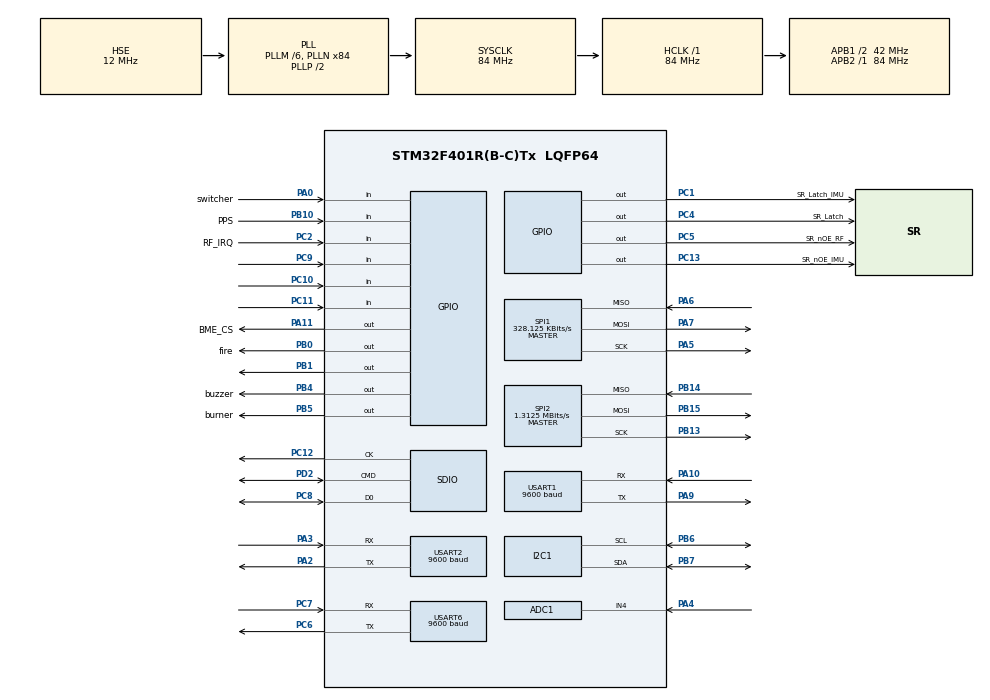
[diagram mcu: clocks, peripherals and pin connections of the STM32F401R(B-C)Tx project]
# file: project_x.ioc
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ADC1.Channel-0\#ChannelRegularConversion=ADC_CHANNEL_4
ADC1.NbrOfConversionFlag=1
ADC1.Rank-0\#ChannelRegularConversion=1
ADC1.SamplingTime-0\#ChannelRegularConversion=ADC_SAMPLETIME_3CYCLES
ADC1.master=1
Dma.Request0=SDIO_TX
Dma.Request1=SDIO_RX
Dma.SDIO_RX.1.Direction=DMA_PERIPH_TO_MEMORY
Dma.SDIO_RX.1.FIFOMode=DMA_FIFOMODE_ENABLE
Dma.SDIO_RX.1.FIFOThreshold=DMA_FIFO_THRESHOLD_FULL
Dma.SDIO_RX.1.Instance=DMA2_Stream6
Dma.SDIO_RX.1.MemBurst=DMA_MBURST_INC4
Dma.SDIO_RX.1.MemDataAlignment=DMA_MDATAALIGN_WORD
Dma.SDIO_RX.1.MemInc=DMA_MINC_ENABLE
Dma.SDIO_RX.1.Mode=DMA_PFCTRL
Dma.SDIO_RX.1.PeriphBurst=DMA_PBURST_INC4
Dma.SDIO_RX.1.PeriphDataAlignment=DMA_PDATAALIGN_WORD
Dma.SDIO_RX.1.PeriphInc=DMA_PINC_DISABLE
Dma.SDIO_RX.1.Priority=DMA_PRIORITY_LOW
Dma.SDIO_TX.0.Direction=DMA_MEMORY_TO_PERIPH
Dma.SDIO_TX.0.FIFOMode=DMA_FIFOMODE_ENABLE
Dma.SDIO_TX.0.FIFOThreshold=DMA_FIFO_THRESHOLD_FULL
Dma.SDIO_TX.0.Instance=DMA2_Stream3
Dma.SDIO_TX.0.MemBurst=DMA_MBURST_INC4
Dma.SDIO_TX.0.MemDataAlignment=DMA_MDATAALIGN_WORD
Dma.SDIO_TX.0.MemInc=DMA_MINC_ENABLE
Dma.SDIO_TX.0.Mode=DMA_PFCTRL
Dma.SDIO_TX.0.PeriphBurst=DMA_PBURST_INC4
Dma.SDIO_TX.0.PeriphDataAlignment=DMA_PDATAALIGN_WORD
Dma.SDIO_TX.0.PeriphInc=DMA_PINC_DISABLE
Dma.SDIO_TX.0.Priority=DMA_PRIORITY_LOW
FATFS._FS_LOCK=10
FATFS._MAX_SS=4096
FATFS._USE_LFN=1
Mcu.Family=STM32F4
Mcu.Name=STM32F401R(B-C)Tx
Mcu.Package=LQFP64
NVIC.DMA2_Stream3_IRQn=true\:0\:0\:false\:false\:true\:false\:true
NVIC.DMA2_Stream6_IRQn=true\:0\:0\:false\:false\:true\:false\:true
NVIC.PriorityGroup=NVIC_PRIORITYGROUP_4
NVIC.USART1_IRQn=true\:0\:0\:false\:false\:true\:true\:true
NVIC.USART6_IRQn=true\:0\:0\:false\:false\:true\:true\:true
PA0-WKUP.GPIO_Label=switcher
PA0-WKUP.Signal=GPIO_Input
PA10.Mode=Asynchronous
PA10.Signal=USART1_RX
PA11.GPIO_Label=BME_CS
PA11.Signal=GPIO_Output
PA13.Mode=Serial_Wire
PA13.Signal=SYS_JTMS-SWDIO
PA14.Mode=Serial_Wire
PA14.Signal=SYS_JTCK-SWCLK
PA2.Mode=Asynchronous
PA2.Signal=USART2_TX
PA3.Mode=Asynchronous
PA3.Signal=USART2_RX
PA4.Signal=ADCx_IN4
PA5.Mode=Full_Duplex_Master
PA5.Signal=SPI1_SCK
PA6.Mode=Full_Duplex_Master
PA6.Signal=SPI1_MISO
PA7.Mode=Full_Duplex_Master
PA7.Signal=SPI1_MOSI
PA9.Mode=Asynchronous
PA9.Signal=USART1_TX
PB0.GPIO_Label=fire
PB0.GPIO_ModeDefaultOutputPP=GPIO_MODE_OUTPUT_OD
PB0.GPIO_PuPd=GPIO_NOPULL
PB0.PinState=GPIO_PIN_SET
PB0.Signal=GPIO_Output
PB1.Signal=GPIO_Output
PB10.GPIO_Label=PPS
PB10.Signal=GPIO_Input
PB13.Mode=Full_Duplex_Master
PB13.Signal=SPI2_SCK
PB14.Mode=Full_Duplex_Master
PB14.Signal=SPI2_MISO
PB15.Mode=Full_Duplex_Master
PB15.Signal=SPI2_MOSI
PB4.GPIO_Label=buzzer
PB4.Signal=GPIO_Output
PB5.GPIO_Label=burner
PB5.Signal=GPIO_Output
PB6.Mode=I2C
PB6.Signal=I2C1_SCL
PB7.Mode=I2C
PB7.Signal=I2C1_SDA
PC1.GPIO_Label=SR_Latch_IMU
PC1.Signal=GPIO_Output
PC10.Signal=GPIO_Input
PC11.Signal=GPIO_Input
PC12.Mode=SD_1_bit
PC12.Signal=SDIO_CK
PC13-ANTI_TAMP.GPIO_Label=SR_nOE_IMU
PC13-ANTI_TAMP.Signal=GPIO_Output
PC2.GPIO_Label=RF_IRQ
PC2.Signal=GPIO_Input
PC4.GPIO_Label=SR_Latch
PC4.Signal=GPIO_Output
PC5.GPIO_Label=SR_nOE_RF
PC5.Signal=GPIO_Output
PC6.Mode=Asynchronous
PC6.Signal=USART6_TX
PC7.Mode=Asynchronous
PC7.Signal=USART6_RX
PC8.Mode=SD_1_bit
PC8.Signal=SDIO_D0
PC9.Signal=GPIO_Input
PD2.Mode=SD_1_bit
PD2.Signal=SDIO_CMD
PH0\ -\ OSC_IN.Mode=HSE-External-Oscillator
PH0\ -\ OSC_IN.Signal=RCC_OSC_IN
PH1\ -\ OSC_OUT.Mode=HSE-External-Oscillator
PH1\ -\ OSC_OUT.Signal=RCC_OSC_OUT
ProjectManager.HeapSize=0x200
ProjectManager.StackSize=0x400
ProjectManager.TargetToolchain=STM32CubeIDE
RCC.48MHZClocksFreq_Value=42000000
RCC.AHBFreq_Value=84000000
RCC.APB1CLKDivider=RCC_HCLK_DIV2
RCC.APB1Freq_Value=42000000
RCC.APB1TimFreq_Value=84000000
RCC.APB2Freq_Value=84000000
RCC.APB2TimFreq_Value=84000000
RCC.CortexFreq_Value=84000000
RCC.HCLKFreq_Value=84000000
RCC.HSE_VALUE=12000000
RCC.HSI_VALUE=16000000
RCC.LSE_VALUE=32768
RCC.PLLM=6
RCC.PLLN=84
RCC.PLLSourceVirtual=RCC_PLLSOURCE_HSE
RCC.SYSCLKFreq_VALUE=84000000
RCC.SYSCLKSource=RCC_SYSCLKSOURCE_PLLCLK
RCC.VCOOutputFreq_Value=168000000
SDIO.ClockDiv=20
SH.ADCx_IN4.0=ADC1_IN4,IN4
SPI1.BaudRatePrescaler=SPI_BAUDRATEPRESCALER_256
SPI1.CLKPhase=SPI_PHASE_2EDGE
SPI1.CLKPolarity=SPI_POLARITY_HIGH
SPI1.CalculateBaudRate=328.125 KBits/s
SPI1.Direction=SPI_DIRECTION_2LINES
SPI1.Mode=SPI_MODE_MASTER
SPI1.VirtualType=VM_MASTER
SPI2.BaudRatePrescaler=SPI_BAUDRATEPRESCALER_32
SPI2.CalculateBaudRate=1.3125 MBits/s
SPI2.Direction=SPI_DIRECTION_2LINES
SPI2.Mode=SPI_MODE_MASTER
SPI2.VirtualType=VM_MASTER
USART1.BaudRate=9600
USART1.VirtualMode=VM_ASYNC
USART2.BaudRate=9600
USART2.VirtualMode=VM_ASYNC
USART6.BaudRate=9600
USART6.VirtualMode=VM_ASYNC
VP_FATFS_VS_SDIO.Mode=SDIO
board=custom

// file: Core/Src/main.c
/* USER CODE BEGIN Header */
/**
  ******************************************************************************
  * @file           : main.c
  * @brief          : Main program body
  ******************************************************************************
  * @attention
  *
  * Copyright (c) 2023 STMicroelectronics.
  * All rights reserved.
  *
  * This software is licensed under terms that can be found in the LICENSE file
  * in the root directory of this software component.
  * If no LICENSE file comes with this software, it is provided AS-IS.
  *
  ******************************************************************************
  */
/* USER CODE END Header */
#include "main.h"
#include "fatfs.h"

ADC_HandleTypeDef hadc1;

I2C_HandleTypeDef hi2c1;

SD_HandleTypeDef hsd;
DMA_HandleTypeDef hdma_sdio_tx;
DMA_HandleTypeDef hdma_sdio_rx;

SPI_HandleTypeDef hspi1;
SPI_HandleTypeDef hspi2;

UART_HandleTypeDef huart1;
UART_HandleTypeDef huart2;
UART_HandleTypeDef huart6;

void SystemClock_Config(void);
static void MX_GPIO_Init(void);
static void MX_SPI2_Init(void);
static void MX_I2C1_Init(void);
static void MX_SDIO_SD_Init(void);
static void MX_ADC1_Init(void);
static void MX_USART1_UART_Init(void);
static void MX_USART2_UART_Init(void);
static void MX_USART6_UART_Init(void);
static void MX_DMA_Init(void);
static void MX_SPI1_Init(void);

/* USER CODE BEGIN 0 */
void app_main();
/* USER CODE END 0 */

int main(void)
{

  /* MCU Configuration--------------------------------------------------------*/

  /* Reset of all peripherals, Initializes the Flash interface and the Systick. */
  HAL_Init();

  /* Configure the system clock */
  SystemClock_Config();

  /* Initialize all configured peripherals */
  MX_GPIO_Init();
  MX_SPI2_Init();
  MX_I2C1_Init();
  MX_SDIO_SD_Init();
  MX_ADC1_Init();
  MX_USART1_UART_Init();
  MX_FATFS_Init();
  MX_USART2_UART_Init();
  MX_USART6_UART_Init();
  MX_DMA_Init();
  MX_SPI1_Init();
  /* USER CODE BEGIN 2 */
  app_main();
  /* USER CODE END 2 */

  /* Infinite loop */
  while (1)
  {

  }
}

void SystemClock_Config(void)
{
  RCC_OscInitTypeDef RCC_OscInitStruct = {0};
  RCC_ClkInitTypeDef RCC_ClkInitStruct = {0};

  /** Configure the main internal regulator output voltage
  */
  __HAL_RCC_PWR_CLK_ENABLE();
  __HAL_PWR_VOLTAGESCALING_CONFIG(PWR_REGULATOR_VOLTAGE_SCALE2);
  /** Initializes the RCC Oscillators according to the specified parameters
  * in the RCC_OscInitTypeDef structure.
  */
  RCC_OscInitStruct.OscillatorType = RCC_OSCILLATORTYPE_HSE;
  RCC_OscInitStruct.HSEState = RCC_HSE_ON;
  RCC_OscInitStruct.PLL.PLLState = RCC_PLL_ON;
  RCC_OscInitStruct.PLL.PLLSource = RCC_PLLSOURCE_HSE;
  RCC_OscInitStruct.PLL.PLLM = 6;
  RCC_OscInitStruct.PLL.PLLN = 84;
  RCC_OscInitStruct.PLL.PLLP = RCC_PLLP_DIV2;
  RCC_OscInitStruct.PLL.PLLQ = 4;
  if (HAL_RCC_OscConfig(&RCC_OscInitStruct) != HAL_OK)
  {
    Error_Handler();
  }
  /** Initializes the CPU, AHB and APB buses clocks
  */
  RCC_ClkInitStruct.ClockType = RCC_CLOCKTYPE_HCLK|RCC_CLOCKTYPE_SYSCLK
                              |RCC_CLOCKTYPE_PCLK1|RCC_CLOCKTYPE_PCLK2;
  RCC_ClkInitStruct.SYSCLKSource = RCC_SYSCLKSOURCE_PLLCLK;
  RCC_ClkInitStruct.AHBCLKDivider = RCC_SYSCLK_DIV1;
  RCC_ClkInitStruct.APB1CLKDivider = RCC_HCLK_DIV2;
  RCC_ClkInitStruct.APB2CLKDivider = RCC_HCLK_DIV1;

  if (HAL_RCC_ClockConfig(&RCC_ClkInitStruct, FLASH_LATENCY_2) != HAL_OK)
  {
    Error_Handler();
  }
}

static void MX_ADC1_Init(void)
{

  ADC_ChannelConfTypeDef sConfig = {0};

  /** Configure the global features of the ADC (Clock, Resolution, Data Alignment and number of conversion)
  */
  hadc1.Instance = ADC1;
  hadc1.Init.ClockPrescaler = ADC_CLOCK_SYNC_PCLK_DIV4;
  hadc1.Init.Resolution = ADC_RESOLUTION_12B;
  hadc1.Init.ScanConvMode = DISABLE;
  hadc1.Init.ContinuousConvMode = DISABLE;
  hadc1.Init.DiscontinuousConvMode = DISABLE;
  hadc1.Init.ExternalTrigConvEdge = ADC_EXTERNALTRIGCONVEDGE_NONE;
  hadc1.Init.ExternalTrigConv = ADC_SOFTWARE_START;
  hadc1.Init.DataAlign = ADC_DATAALIGN_RIGHT;
  hadc1.Init.NbrOfConversion = 1;
  hadc1.Init.DMAContinuousRequests = DISABLE;
  hadc1.Init.EOCSelection = ADC_EOC_SINGLE_CONV;
  if (HAL_ADC_Init(&hadc1) != HAL_OK)
  {
    Error_Handler();
  }
  /** Configure for the selected ADC regular channel its corresponding rank in the sequencer and its sample time.
  */
  sConfig.Channel = ADC_CHANNEL_4;
  sConfig.Rank = 1;
  sConfig.SamplingTime = ADC_SAMPLETIME_3CYCLES;
  if (HAL_ADC_ConfigChannel(&hadc1, &sConfig) != HAL_OK)
  {
    Error_Handler();
  }

}

static void MX_I2C1_Init(void)
{

  hi2c1.Instance = I2C1;
  hi2c1.Init.ClockSpeed = 100000;
  hi2c1.Init.DutyCycle = I2C_DUTYCYCLE_2;
  hi2c1.Init.OwnAddress1 = 0;
  hi2c1.Init.AddressingMode = I2C_ADDRESSINGMODE_7BIT;
  hi2c1.Init.DualAddressMode = I2C_DUALADDRESS_DISABLE;
  hi2c1.Init.OwnAddress2 = 0;
  hi2c1.Init.GeneralCallMode = I2C_GENERALCALL_DISABLE;
  hi2c1.Init.NoStretchMode = I2C_NOSTRETCH_DISABLE;
  if (HAL_I2C_Init(&hi2c1) != HAL_OK)
  {
    Error_Handler();
  }

}

static void MX_SDIO_SD_Init(void)
{

  hsd.Instance = SDIO;
  hsd.Init.ClockEdge = SDIO_CLOCK_EDGE_RISING;
  hsd.Init.ClockBypass = SDIO_CLOCK_BYPASS_DISABLE;
  hsd.Init.ClockPowerSave = SDIO_CLOCK_POWER_SAVE_DISABLE;
  hsd.Init.BusWide = SDIO_BUS_WIDE_1B;
  hsd.Init.HardwareFlowControl = SDIO_HARDWARE_FLOW_CONTROL_DISABLE;
  hsd.Init.ClockDiv = 20;

}

static void MX_SPI1_Init(void)
{

  /* SPI1 parameter configuration*/
  hspi1.Instance = SPI1;
  hspi1.Init.Mode = SPI_MODE_MASTER;
  hspi1.Init.Direction = SPI_DIRECTION_2LINES;
  hspi1.Init.DataSize = SPI_DATASIZE_8BIT;
  hspi1.Init.CLKPolarity = SPI_POLARITY_HIGH;
  hspi1.Init.CLKPhase = SPI_PHASE_2EDGE;
  hspi1.Init.NSS = SPI_NSS_SOFT;
  hspi1.Init.BaudRatePrescaler = SPI_BAUDRATEPRESCALER_256;
  hspi1.Init.FirstBit = SPI_FIRSTBIT_MSB;
  hspi1.Init.TIMode = SPI_TIMODE_DISABLE;
  hspi1.Init.CRCCalculation = SPI_CRCCALCULATION_DISABLE;
  hspi1.Init.CRCPolynomial = 10;
  if (HAL_SPI_Init(&hspi1) != HAL_OK)
  {
    Error_Handler();
  }

}

static void MX_SPI2_Init(void)
{

  /* SPI2 parameter configuration*/
  hspi2.Instance = SPI2;
  hspi2.Init.Mode = SPI_MODE_MASTER;
  hspi2.Init.Direction = SPI_DIRECTION_2LINES;
  hspi2.Init.DataSize = SPI_DATASIZE_8BIT;
  hspi2.Init.CLKPolarity = SPI_POLARITY_LOW;
  hspi2.Init.CLKPhase = SPI_PHASE_1EDGE;
  hspi2.Init.NSS = SPI_NSS_SOFT;
  hspi2.Init.BaudRatePrescaler = SPI_BAUDRATEPRESCALER_32;
  hspi2.Init.FirstBit = SPI_FIRSTBIT_MSB;
  hspi2.Init.TIMode = SPI_TIMODE_DISABLE;
  hspi2.Init.CRCCalculation = SPI_CRCCALCULATION_DISABLE;
  hspi2.Init.CRCPolynomial = 10;
  if (HAL_SPI_Init(&hspi2) != HAL_OK)
  {
    Error_Handler();
  }

}

static void MX_USART1_UART_Init(void)
{

  huart1.Instance = USART1;
  huart1.Init.BaudRate = 9600;
  huart1.Init.WordLength = UART_WORDLENGTH_8B;
  huart1.Init.StopBits = UART_STOPBITS_1;
  huart1.Init.Parity = UART_PARITY_NONE;
  huart1.Init.Mode = UART_MODE_TX_RX;
  huart1.Init.HwFlowCtl = UART_HWCONTROL_NONE;
  huart1.Init.OverSampling = UART_OVERSAMPLING_16;
  if (HAL_UART_Init(&huart1) != HAL_OK)
  {
    Error_Handler();
  }

}

static void MX_USART2_UART_Init(void)
{

  huart2.Instance = USART2;
  huart2.Init.BaudRate = 9600;
  huart2.Init.WordLength = UART_WORDLENGTH_8B;
  huart2.Init.StopBits = UART_STOPBITS_1;
  huart2.Init.Parity = UART_PARITY_NONE;
  huart2.Init.Mode = UART_MODE_TX_RX;
  huart2.Init.HwFlowCtl = UART_HWCONTROL_NONE;
  huart2.Init.OverSampling = UART_OVERSAMPLING_16;
  if (HAL_UART_Init(&huart2) != HAL_OK)
  {
    Error_Handler();
  }

}

static void MX_USART6_UART_Init(void)
{

  huart6.Instance = USART6;
  huart6.Init.BaudRate = 9600;
  huart6.Init.WordLength = UART_WORDLENGTH_8B;
  huart6.Init.StopBits = UART_STOPBITS_1;
  huart6.Init.Parity = UART_PARITY_NONE;
  huart6.Init.Mode = UART_MODE_TX_RX;
  huart6.Init.HwFlowCtl = UART_HWCONTROL_NONE;
  huart6.Init.OverSampling = UART_OVERSAMPLING_16;
  if (HAL_UART_Init(&huart6) != HAL_OK)
  {
    Error_Handler();
  }

}

static void MX_DMA_Init(void)
{

  /* DMA controller clock enable */
  __HAL_RCC_DMA2_CLK_ENABLE();

  /* DMA interrupt init */
  /* DMA2_Stream3_IRQn interrupt configuration */
  HAL_NVIC_SetPriority(DMA2_Stream3_IRQn, 0, 0);
  HAL_NVIC_EnableIRQ(DMA2_Stream3_IRQn);
  /* DMA2_Stream6_IRQn interrupt configuration */
  HAL_NVIC_SetPriority(DMA2_Stream6_IRQn, 0, 0);
  HAL_NVIC_EnableIRQ(DMA2_Stream6_IRQn);

}

static void MX_GPIO_Init(void)
{
  GPIO_InitTypeDef GPIO_InitStruct = {0};

  /* GPIO Ports Clock Enable */
  __HAL_RCC_GPIOC_CLK_ENABLE();
  __HAL_RCC_GPIOH_CLK_ENABLE();
  __HAL_RCC_GPIOA_CLK_ENABLE();
  __HAL_RCC_GPIOB_CLK_ENABLE();
  __HAL_RCC_GPIOD_CLK_ENABLE();

  /*Configure GPIO pin Output Level */
  HAL_GPIO_WritePin(GPIOC, SR_nOE_IMU_Pin|SR_Latch_IMU_Pin|SR_Latch_Pin|SR_nOE_RF_Pin, GPIO_PIN_RESET);

  /*Configure GPIO pin Output Level */
  HAL_GPIO_WritePin(fire_GPIO_Port, fire_Pin, GPIO_PIN_SET);

  /*Configure GPIO pin Output Level */
  HAL_GPIO_WritePin(GPIOB, GPIO_PIN_1|buzzer_Pin|burner_Pin, GPIO_PIN_RESET);

  /*Configure GPIO pin Output Level */
  HAL_GPIO_WritePin(BME_CS_GPIO_Port, BME_CS_Pin, GPIO_PIN_RESET);

  /*Configure GPIO pins : SR_nOE_IMU_Pin SR_Latch_IMU_Pin SR_Latch_Pin SR_nOE_RF_Pin */
  GPIO_InitStruct.Pin = SR_nOE_IMU_Pin|SR_Latch_IMU_Pin|SR_Latch_Pin|SR_nOE_RF_Pin;
  GPIO_InitStruct.Mode = GPIO_MODE_OUTPUT_PP;
  GPIO_InitStruct.Pull = GPIO_NOPULL;
  GPIO_InitStruct.Speed = GPIO_SPEED_FREQ_LOW;
  HAL_GPIO_Init(GPIOC, &GPIO_InitStruct);

  /*Configure GPIO pins : RF_IRQ_Pin PC9 PC10 PC11 */
  GPIO_InitStruct.Pin = RF_IRQ_Pin|GPIO_PIN_9|GPIO_PIN_10|GPIO_PIN_11;
  GPIO_InitStruct.Mode = GPIO_MODE_INPUT;
  GPIO_InitStruct.Pull = GPIO_NOPULL;
  HAL_GPIO_Init(GPIOC, &GPIO_InitStruct);

  /*Configure GPIO pin : switcher_Pin */
  GPIO_InitStruct.Pin = switcher_Pin;
  GPIO_InitStruct.Mode = GPIO_MODE_INPUT;
  GPIO_InitStruct.Pull = GPIO_NOPULL;
  HAL_GPIO_Init(switcher_GPIO_Port, &GPIO_InitStruct);

  /*Configure GPIO pin : fire_Pin */
  GPIO_InitStruct.Pin = fire_Pin;
  GPIO_InitStruct.Mode = GPIO_MODE_OUTPUT_OD;
  GPIO_InitStruct.Pull = GPIO_NOPULL;
  GPIO_InitStruct.Speed = GPIO_SPEED_FREQ_LOW;
  HAL_GPIO_Init(fire_GPIO_Port, &GPIO_InitStruct);

  /*Configure GPIO pins : PB1 buzzer_Pin burner_Pin */
  GPIO_InitStruct.Pin = GPIO_PIN_1|buzzer_Pin|burner_Pin;
  GPIO_InitStruct.Mode = GPIO_MODE_OUTPUT_PP;
  GPIO_InitStruct.Pull = GPIO_NOPULL;
  GPIO_InitStruct.Speed = GPIO_SPEED_FREQ_LOW;
  HAL_GPIO_Init(GPIOB, &GPIO_InitStruct);

  /*Configure GPIO pin : PPS_Pin */
  GPIO_InitStruct.Pin = PPS_Pin;
  GPIO_InitStruct.Mode = GPIO_MODE_INPUT;
  GPIO_InitStruct.Pull = GPIO_NOPULL;
  HAL_GPIO_Init(PPS_GPIO_Port, &GPIO_InitStruct);

  /*Configure GPIO pin : BME_CS_Pin */
  GPIO_InitStruct.Pin = BME_CS_Pin;
  GPIO_InitStruct.Mode = GPIO_MODE_OUTPUT_PP;
  GPIO_InitStruct.Pull = GPIO_NOPULL;
  GPIO_InitStruct.Speed = GPIO_SPEED_FREQ_LOW;
  HAL_GPIO_Init(BME_CS_GPIO_Port, &GPIO_InitStruct);

}

void Error_Handler(void)
{
  __disable_irq();
  while (1)
  {
  }
}
